# D2522AA register map
Vendor: Dialog; Series: D2522AA; File version: 1.2
CPU: CM0 r1p0, little endian, MPU, FPU, 3 interrupt priority bits
Registers are 32-bit, read-write, reset 0x0 unless marked. A register's access mark holds for its fields unless they carry their own. Offsets are from the block's base; [hi:lo] are bit positions; {n}, {i} and the like mark numbered series.

## SMOTOR — SMOTOR registers
Base 0x50030E00
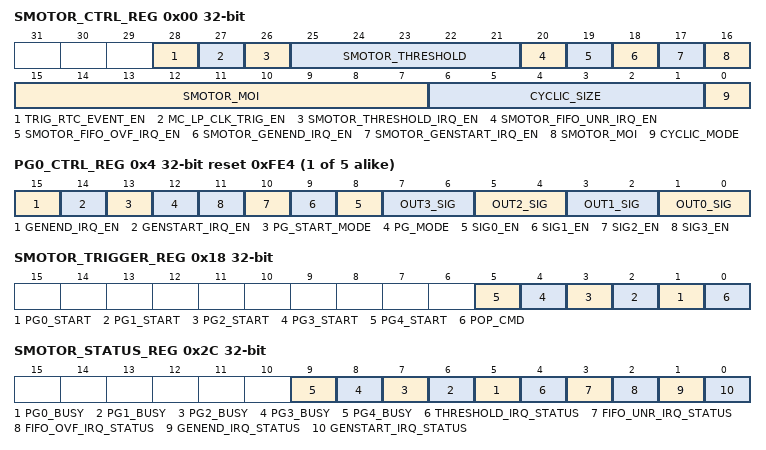
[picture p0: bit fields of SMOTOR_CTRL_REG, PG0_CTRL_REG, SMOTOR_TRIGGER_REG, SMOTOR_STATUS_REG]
0x00 SMOTOR_CTRL_REG — Motor control register
  [28] TRIG_RTC_EVENT_EN — 0 = RTC event does not trigger command pop 1 = RTC even triggers command pop
  [27] MC_LP_CLK_TRIG_EN — 0 = Divided sleep clock does not trigger command pop 1 = Divided sleep clock triggers command pop
  [26] SMOTOR_THRESHOLD_IRQ_EN — IRQ in the event of the FIFO level (write pointer - read pointer) reaching, or is below the threshold determined by SMOTOR_THRESHOLD. 0 = Interrupt requests disabled 1 = Interrupt requests enabled
  [25:21] SMOTOR_THRESHOLD — Determines the FIFO level (write pointer - read pointer) at or below which and IRQ can be triggered using SMOTOR_THRESHOLD_IRQ_EN.
  [20] SMOTOR_FIFO_UNR_IRQ_EN — IRQ in the event of FIFO underrun: 0 = Interrupt requests disabled 1 = Interrupt requests enabled
  [19] SMOTOR_FIFO_OVF_IRQ_EN — IRQ in the event of FIFO overflow: 0 = IRQ is disabled 1 = IRQ is enabled
  [18] SMOTOR_GENEND_IRQ_EN — IRQ in the event a pattern generator (configured to do so through its corresponding GENEND_IRQ_EN bit) has ended generating a pattern: 0 = Interrupt requests disabled 1 = Interrupt requests enabled
  [17] SMOTOR_GENSTART_IRQ_EN — IRQ in the event a pattern generator (configured to do so through its corresponding GENSTART_IRQ_EN bit) has just started generating a pattern: 0 = Interrupt requests disabled 1 = Interrupt requests enabled
  [16:7] SMOTOR_MOI — Idle time of a PG after generating a waveform. A PG will remain busy for the last signal's MOI to finish.
  [6:1] CYCLIC_SIZE — Depth of the cyclic buffer, only valid if CYCLIC_MODE is 1
  [0] CYCLIC_MODE — Determines operation mode of command FIFO: 0 = Normal FIFO mode 1 = Cyclic buffer mode, CYCLIC_SIZE determines buffer depth
{0x4+4i} PG{i}_CTRL_REG reset 0xFE4 (i=0..4) — Pattern generator {i} control register
  [15] GENEND_IRQ_EN — Determines if the corresponding pattern generator will contribute to the generation of the IRQ when it is done generating a pattern. It is only valid if SMOTOR_GENEND_IRQ_EN is enabled: 0 = Interrupt requests disabled 1 = Interrupt requests enabled
  [14] GENSTART_IRQ_EN — Determines if the corresponding pattern generator will contribute to the generation of the IRQ when it starts generating a pattern. It is only valid if SMOTOR_GENSTART_IRQ_EN is enabled: 0 = Interrupt requests disabled 1 = Interrupt requests enabled
  [13] PG_START_MODE — 0 = Auto start mode: pattern generator will start whenever all enabled signals have received a command 1 = Manual start mode: pattern generator will only start if it has been given a PG_START, and all enabled signals have received a command
  [12] PG_MODE — 0 = Flex mode 1 = Pair mode
  [n+8] SIG{n}_EN (n=0..3) — 0 = Signal disabled 1 = Signal enabled
  [2n+1:2n] OUT{n}_SIG (n=0..3) — Selects which signal is routed to the output.
0x18 SMOTOR_TRIGGER_REG — Motor controller trigger register
  [n+1] PG{n}_START wo (n=0..4) — Writing 1 to this bit will start PG{n} in manual mode.
  [0] POP_CMD wo — Writing 1 will pop one or more commands from the command buffer into its corresponding pattern generator
0x20 SMOTOR_CMD_FIFO_REG — Motor control command FIFO register
  [15:0] SMOTOR_CMD_FIFO wo — Writing to this address will push a command into the command FIFO.
0x24 SMOTOR_CMD_READ_PTR_REG — Command read pointer register
  [5:0] SMOTOR_CMD_READ_PTR ro — Pointer to the next command to be popped from the FIFO. The command at SMOTOR_CMD_READ_PTR-1 is the last command that has been popped from the FIFO into its corresponding PG.
0x28 SMOTOR_CMD_WRITE_PTR_REG — Command write pointer register
  [5:0] SMOTOR_CMD_WRITE_PTR — Pointer to the location in the FIFO where the next command will be pushed at. The last command pushed to the FIFO is at SMOTOR_CMD_WRITE_PTR - 1
0x2C SMOTOR_STATUS_REG — Motor controller status register
  [n+5] PG{n}_BUSY ro (n=0..4) — Tells whether the PG is busy/generating a waveform.
  [4] THRESHOLD_IRQ_STATUS ro — Tells whether the THRESHOLD_IRQ fired. Can be cleared with corresponding _CLEAR bit.
  [3] FIFO_UNR_IRQ_STATUS ro — Tells whether the FIFO_UNR_IRQ fired. Can be cleared with corresponding _CLEAR bit.
  [2] FIFO_OVF_IRQ_STATUS ro — Tells whether the FIFO_OVF_IRQ fired. Can be cleared with corresponding _CLEAR bit.
  [1] GENEND_IRQ_STATUS ro — Tells whether the GENEND_IRQ fired. Can be cleared with corresponding _CLEAR bit.
  [0] GENSTART_IRQ_STATUS ro — Tells whether the GENSTART_IRQ fired. Can be cleared with corresponding _CLEAR bit.
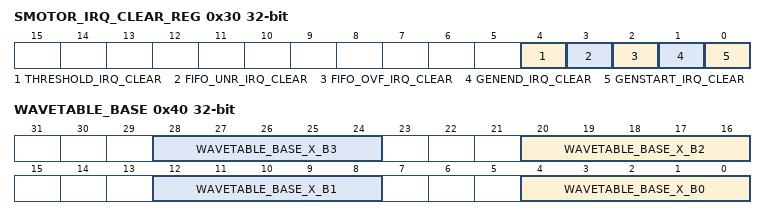
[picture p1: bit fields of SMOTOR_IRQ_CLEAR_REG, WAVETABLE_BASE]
0x30 SMOTOR_IRQ_CLEAR_REG — Motor control IRQ clear register
  [4] THRESHOLD_IRQ_CLEAR wo — Clears the THRESHOLD_IRQ_STATUS bit.
  [3] FIFO_UNR_IRQ_CLEAR wo — Clears the FIFO_UNR_IRQ_STATUS bit.
  [2] FIFO_OVF_IRQ_CLEAR wo — Clears the FIFO_OVF_IRQ_STATUS bit.
  [1] GENEND_IRQ_CLEAR wo — Clears the GENEND_IRQ_CLEAR bit.
  [0] GENSTART_IRQ_CLEAR wo — Clears the GENSTART_IRQ_CLEAR bit.
0x40 WAVETABLE_BASE — Base address of the wavetable
  [8n+4:8n] WAVETABLE_BASE_X_B{n} (n=0..3) — Dummy bitfield for register test generation.
0x80 CMD_TABLE_BASE (reset mask 0x7FFFFFFF) — Base address of the command table
  [31:0] CMD_TABLE_BASE_X ro — Dummy field for register test generation.
